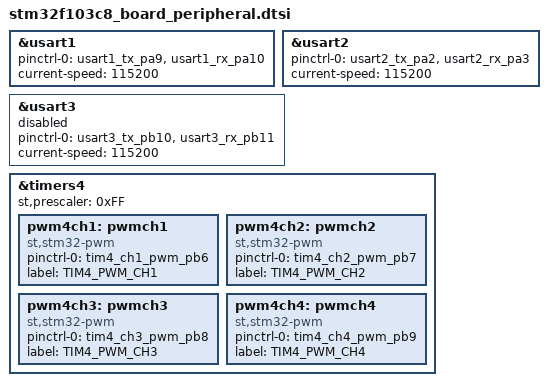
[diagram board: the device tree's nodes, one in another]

/* usart start */
&usart1 {
	pinctrl-0 = <&usart1_tx_pa9 &usart1_rx_pa10>;
	pinctrl-names = "default";
	current-speed = <115200>;
	status = "okay";
};

&usart2 {
	pinctrl-0 = <&usart2_tx_pa2 &usart2_rx_pa3>;
	pinctrl-names = "default";
	current-speed = <115200>;
	status = "okay";
};

&usart3 {
	pinctrl-0 = <&usart3_tx_pb10 &usart3_rx_pb11>;
	pinctrl-names = "default";
	current-speed = <115200>;
	status = "disabled";
};
/* usart end */

/* timer start */
&timers4 {
	status = "okay";
	st,prescaler = <0xFF>;

	// serving timers4 ch1 pwm
	pwm4ch1: pwmch1 {
		compatible = "st,stm32-pwm";
		status = "okay";
		pinctrl-0 = <&tim4_ch1_pwm_pb6>;
		pinctrl-names = "default";
		label = "TIM4_PWM_CH1";
		#pwm-cells = <3>;
	};

	// serving timers4 ch2 pwm
	pwm4ch2: pwmch2 {
		compatible = "st,stm32-pwm";
		status = "okay";
		pinctrl-0 = <&tim4_ch2_pwm_pb7>;
		pinctrl-names = "default";
		label = "TIM4_PWM_CH2";
		#pwm-cells = <3>;
	};

	// serving timers4 ch3 pwm
	pwm4ch3: pwmch3 {
		compatible = "st,stm32-pwm";
		status = "okay";
		pinctrl-0 = <&tim4_ch3_pwm_pb8>;
		pinctrl-names = "default";
		label = "TIM4_PWM_CH3";
		#pwm-cells = <3>;
	};

	// serving timers4 ch4 pwm
	pwm4ch4: pwmch4 {
		compatible = "st,stm32-pwm";
		status = "okay";
		pinctrl-0 = <&tim4_ch4_pwm_pb9>;
		pinctrl-names = "default";
		label = "TIM4_PWM_CH4";
		#pwm-cells = <3>;
	};
};
/* timer end */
